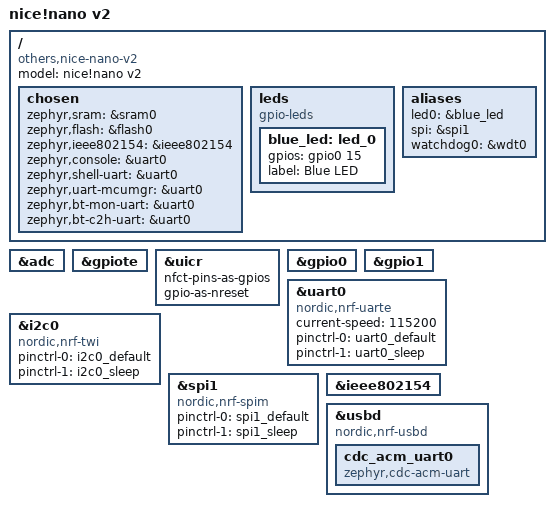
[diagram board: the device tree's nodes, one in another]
/*
 * nice!nano v2 board definition adapted for NCS/Zephyr local builds.
 */

/dts-v1/;
#include <nordic/nrf52840_qiaa.dtsi>
#include "nice_nano_v2-pinctrl.dtsi"
#include "arduino_pro_micro_pins.dtsi"

/ {
	model = "nice!nano v2";
	compatible = "others,nice-nano-v2";

	chosen {
		zephyr,sram = &sram0;
		zephyr,flash = &flash0;
		zephyr,ieee802154 = &ieee802154;
		zephyr,console = &uart0;
		zephyr,shell-uart = &uart0;
		zephyr,uart-mcumgr = &uart0;
		zephyr,bt-mon-uart = &uart0;
		zephyr,bt-c2h-uart = &uart0;
	};

	leds {
		compatible = "gpio-leds";

		blue_led: led_0 {
			gpios = <&gpio0 15 GPIO_ACTIVE_HIGH>;
			label = "Blue LED";
		};
	};

	aliases {
		led0 = &blue_led;
		spi = &spi1;
		watchdog0 = &wdt0;
	};
};

&adc {
	status = "okay";
};

&gpiote {
	status = "okay";
};

&uicr {
	nfct-pins-as-gpios;
	gpio-as-nreset;
};

&gpio0 {
	status = "okay";
};

&gpio1 {
	status = "okay";
};

&uart0 {
	compatible = "nordic,nrf-uarte";
	status = "okay";
	current-speed = <115200>;
	pinctrl-0 = <&uart0_default>;
	pinctrl-1 = <&uart0_sleep>;
	pinctrl-names = "default", "sleep";
};

&i2c0 {
	compatible = "nordic,nrf-twi";
	status = "okay";
	pinctrl-0 = <&i2c0_default>;
	pinctrl-1 = <&i2c0_sleep>;
	pinctrl-names = "default", "sleep";
};

&spi1 {
	compatible = "nordic,nrf-spim";
	status = "okay";
	pinctrl-0 = <&spi1_default>;
	pinctrl-1 = <&spi1_sleep>;
	pinctrl-names = "default", "sleep";
};

&ieee802154 {
	status = "okay";
};

zephyr_udc0: &usbd {
	compatible = "nordic,nrf-usbd";
	status = "okay";

	cdc_acm_uart0: cdc_acm_uart0 {
		compatible = "zephyr,cdc-acm-uart";
	};
};
